# OCMC_RAM1 register map
Vendor: Texas Instruments
Peripheral module from a debugger description file (folder DRA74xP_75xP_76xP_77xP).
Registers are 32-bit, access per field, reset values left out (the file's numbers can be read two ways) unless marked. A register's access mark holds for its fields unless they carry their own. Offsets are as the file gives them; lines under a group give offsets from that group; [hi:lo] are bit positions; {n}, {i} and the like mark numbered series; 'fields as' and 'values as' point back to an identical list; <NAME> marks a mode.

## OCMC_RAM1
0x00 OCMC_ECC_PID ro
  [31:0] REVISION — TI internal data
0x04 OCMC_SYSCONFIG_PM
  [3:2] IDLEMODE rw — Configuration of the local target state management mode. By definition, target can handle read/write transaction as long as it is out of IDLE state.
    0=IP_0 (Force-idle mode: local target's idle state follows (acknowledges) the system's idle requests unconditionally, that is, regardless of the IP module's internal requirements. Backup mode, for debug only.); 1=No-idle mode: local target never enters idle state. Backup mode, for debug only; 2=IP_IP_2 (Smart-idle mode: local target's idle state eventually follows (acknowledges) the system's idle requests, depending on the IP module's internal requirements. IP module shall not generate IRQ-request-related wakeup events.); 3=IP_IP_3 (Smart-idle wakeup-capable mode: local target’s idle state eventually follows (acknowledges) the system’s idle requests, depending on the IP module’s internal requirements. IP module may generate IRQ-request-related wakeup events when in idle state.)
0x08 OCMC_SYSCONFIG_RST
  [0] SW_RST rw — Software reset of the OCM controller configuration and history logic (does not reset L4 interface)
    0=NORMAL_OP (Normal operation (OCM controller is not reset)); 1=RESET (Reset the OCM controller (except its registers). This bit must be set back to 0x0 to resume the normal operation of the OCM Controller.)
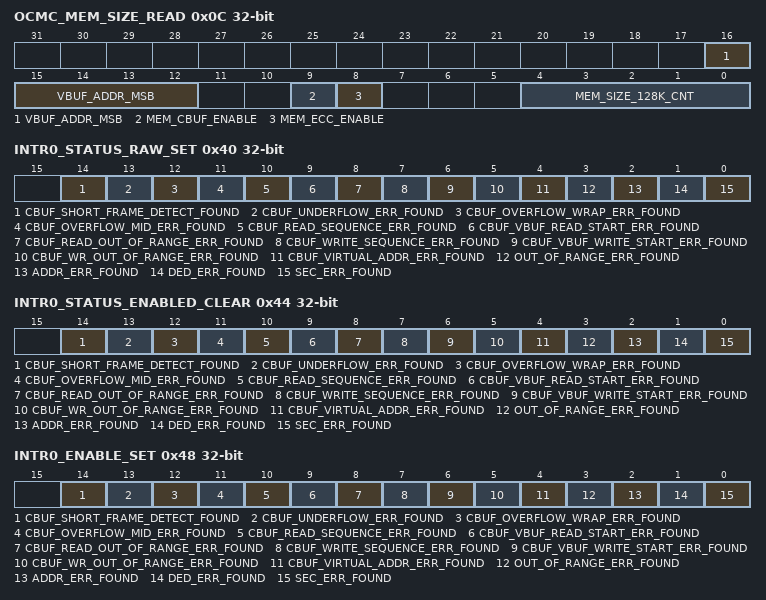
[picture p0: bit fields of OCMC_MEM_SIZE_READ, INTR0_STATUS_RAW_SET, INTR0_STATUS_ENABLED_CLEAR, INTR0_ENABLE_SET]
0x0C OCMC_MEM_SIZE_READ ro — This register provides the status of the OCM Controller configuration.
  [16:12] VBUF_ADDR_MSB — This bit field returns the MSB bit of the valid VBUF address range. The default value of 23 means that the valid VBUF address range is from 0x8000 0000 to 0x80FF FFFF
  [9] MEM_CBUF_ENABLE — Indicates whether CBUF is supported or not.
    0=CBUF_ECC_OFF (CBUF not supported); 1=CBUF_ECC_ON (CBUF supported)
  [8] MEM_ECC_ENABLE — Indicates whether ECC is supported or not.
    0=ECC_OFF (ECC not supported); 1=ECC_ON (ECC supported)
  [4:0] MEM_SIZE_128K_CNT — This bit field indicates how many 128KiB memory blocks are present in the SRAM. Access beyond the memory size reported in the MEM_SIZE_128K_CNT bit field results in an address error interrupt. 0x1: One 128KiB memory block 0x2: Two 128KiB memory blocks ... 0x14: 20 memory blocks of 128KiB
0x40 INTR0_STATUS_RAW_SET — This register contains the raw interrupt status. Read indicates RAW interrupt status (0=inactive, 1=active). Writing 1 will SET the corresponding raw status bit (soft interrupt set). Writing 0 has no effect.
  [14] CBUF_SHORT_FRAME_DETECT_FOUND rw — CBUF detected short frame.
  [13] CBUF_UNDERFLOW_ERR_FOUND rw
  [12] CBUF_OVERFLOW_WRAP_ERR_FOUND rw
  [11] CBUF_OVERFLOW_MID_ERR_FOUND rw
  [10] CBUF_READ_SEQUENCE_ERR_FOUND rw
  [9] CBUF_VBUF_READ_START_ERR_FOUND rw
  [8] CBUF_READ_OUT_OF_RANGE_ERR_FOUND rw
  [7] CBUF_WRITE_SEQUENCE_ERR_FOUND rw
  [6] CBUF_VBUF_WRITE_START_ERR_FOUND rw
  [5] CBUF_WR_OUT_OF_RANGE_ERR_FOUND rw
  [4] CBUF_VIRTUAL_ADDR_ERR_FOUND rw
  [3] OUT_OF_RANGE_ERR_FOUND rw
  [2] ADDR_ERR_FOUND rw
  [1] DED_ERR_FOUND rw
  [0] SEC_ERR_FOUND rw
0x44 INTR0_STATUS_ENABLED_CLEAR access not given — Read indicates ENABLED interrupt status (0=inactive, 1=active). Writing 1 will CLEAR the corresponding enabled status bit. Writing 0 has no effect.
  [14] CBUF_SHORT_FRAME_DETECT_FOUND — CBUF detected short frame (access RW W1toClr)
  [13] CBUF_UNDERFLOW_ERR_FOUND — (access RW W1toClr)
  [12] CBUF_OVERFLOW_WRAP_ERR_FOUND — (access RW W1toClr)
  [11] CBUF_OVERFLOW_MID_ERR_FOUND — (access RW W1toClr)
  [10] CBUF_READ_SEQUENCE_ERR_FOUND — (access RW W1toClr)
  [9] CBUF_VBUF_READ_START_ERR_FOUND — (access RW W1toClr)
  [8] CBUF_READ_OUT_OF_RANGE_ERR_FOUND — (access RW W1toClr)
  [7] CBUF_WRITE_SEQUENCE_ERR_FOUND — (access RW W1toClr)
  [6] CBUF_VBUF_WRITE_START_ERR_FOUND — (access RW W1toClr)
  [5] CBUF_WR_OUT_OF_RANGE_ERR_FOUND — (access RW W1toClr)
  [4] CBUF_VIRTUAL_ADDR_ERR_FOUND — (access RW W1toClr)
  [3] OUT_OF_RANGE_ERR_FOUND — (access RW W1toClr)
  [2] ADDR_ERR_FOUND — (access RW W1toClr)
  [1] DED_ERR_FOUND — (access RW W1toClr)
  [0] SEC_ERR_FOUND — (access RW W1toClr)
0x48 INTR0_ENABLE_SET — Read indicates interrupt enable (0=disabled, 1=enabled) Writing 1 will set the corresponding interrupt enable bit. Writing 0 has no effect. Interrupt_enable_set
  [14] CBUF_SHORT_FRAME_DETECT_FOUND rw — CBUF detected short frame
  [13] CBUF_UNDERFLOW_ERR_FOUND rw
  [12] CBUF_OVERFLOW_WRAP_ERR_FOUND rw
  [11] CBUF_OVERFLOW_MID_ERR_FOUND rw
  [10] CBUF_READ_SEQUENCE_ERR_FOUND rw
  [9] CBUF_VBUF_READ_START_ERR_FOUND rw
  [8] CBUF_READ_OUT_OF_RANGE_ERR_FOUND rw
  [7] CBUF_WRITE_SEQUENCE_ERR_FOUND rw
  [6] CBUF_VBUF_WRITE_START_ERR_FOUND rw
  [5] CBUF_WR_OUT_OF_RANGE_ERR_FOUND rw
  [4] CBUF_VIRTUAL_ADDR_ERR_FOUND rw
  [3] OUT_OF_RANGE_ERR_FOUND rw
  [2] ADDR_ERR_FOUND rw
  [1] DED_ERR_FOUND rw
  [0] SEC_ERR_FOUND rw
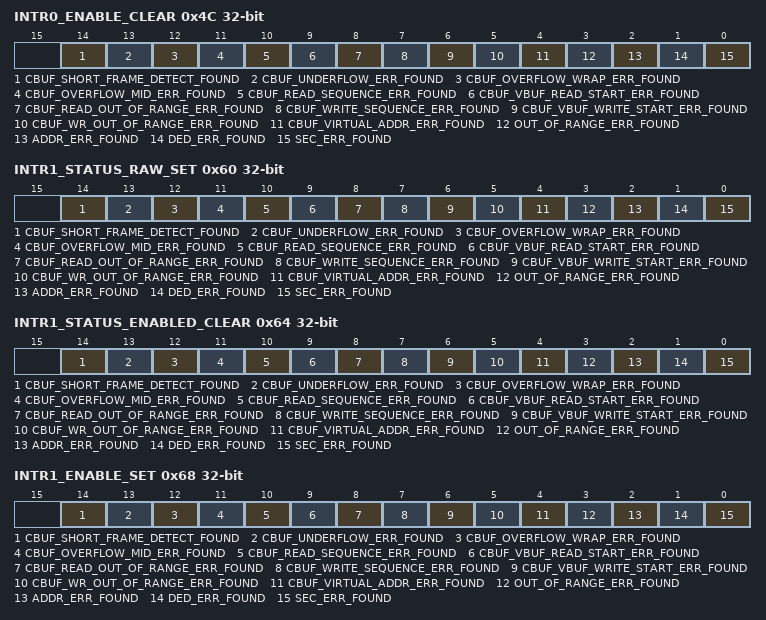
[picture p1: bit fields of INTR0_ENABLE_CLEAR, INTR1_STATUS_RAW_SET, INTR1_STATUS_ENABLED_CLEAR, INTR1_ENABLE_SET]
0x4C INTR0_ENABLE_CLEAR access not given — Read indicates interrupt enable (0=disabled, 1=enabled) Writing 1 will clear interrupt enabled. Writing 0 has no effect. Interrupt_enable_clear
  fields as INTR0_STATUS_ENABLED_CLEAR
0x50 OCMC_INTR0_EOI — This register contains the EOI vector.
  [0] EOI_VECTOR rw
0x60 INTR1_STATUS_RAW_SET — This register contains the raw interrupt status. Read indicates RAW interrupt status (0=inactive, 1=active). Writing 1 will SET the corresponding raw status bit (soft interrupt set). Writing 0 has no effect.
  fields as INTR0_ENABLE_SET
0x64 INTR1_STATUS_ENABLED_CLEAR access not given — Read indicates ENABLED interrupt status (0=inactive, 1=active). Writing 1 will CLEAR the corresponding enabled status bit. Writing 0 has no effect.
  fields as INTR0_STATUS_ENABLED_CLEAR
0x68 INTR1_ENABLE_SET — Read indicates interrupt enable (0=disabled, 1=enabled) Writing 1 will set the corresponding interrupt enable bit. Writing 0 has no effect. Interrupt_enable_set
  fields as INTR0_ENABLE_SET
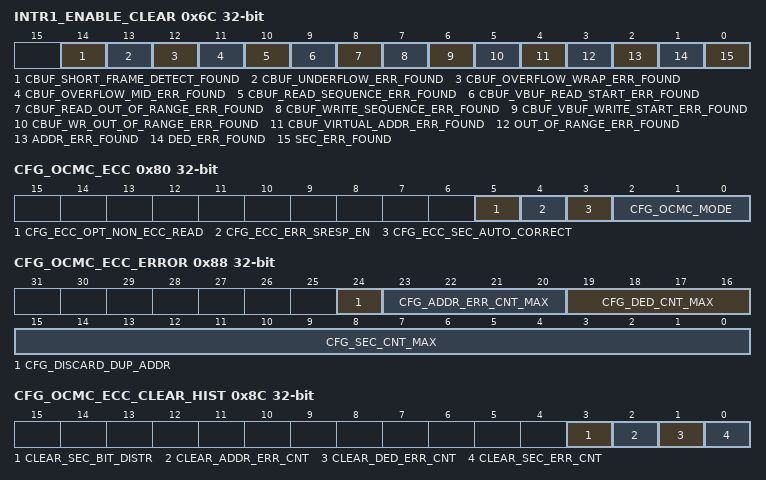
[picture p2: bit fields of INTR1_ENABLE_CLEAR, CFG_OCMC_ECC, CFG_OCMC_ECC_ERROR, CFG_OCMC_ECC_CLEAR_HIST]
0x6C INTR1_ENABLE_CLEAR access not given — Read indicates interrupt enable (0=disabled, 1=enabled) Writing 1 will clear interrupt enabled. Writing 0 has no effect. Interrupt_enable_clear
  fields as INTR0_STATUS_ENABLED_CLEAR
0x70 OCMC_INTR1_EOI — This register contains the EOI vector.
  [0] EOI_VECTOR rw
0x80 CFG_OCMC_ECC
  [5] CFG_ECC_OPT_NON_ECC_READ rw — Optimize read latency for non-ECC read. Returns the data one cycle faster if the read access is from a non-ECC enabled space. 0x0: Disable 0x1: Enable
  [4] CFG_ECC_ERR_SRESP_EN rw — ECC non-correctable error SRESP enable. Enables ERR return on L3 OCP SRESP when a non-correctable data (DED) or address error is detected. 0x0: Disable 0x1: Enable
  [3] CFG_ECC_SEC_AUTO_CORRECT rw — SEC error auto correction mode. Enables the OCM Controller to automatically update the wrong data word with the corrected word. 0x0: Disable 0x1: Enable (If the OCM Controller is performing a read-modify operation for a sub-128b write to an ECC enabled memory, the error found during the read phase will be corrected always regardless of the value of this bit)
  [2:0] CFG_OCMC_MODE rw — OCM Controller memory access modes. 0x0: Non-ECC mode (data access) 0x1: Non-ECC mode (code access) 0x2: Full ECC enabled mode 0x3: Block ECC enabled mode 0x4-0x7: Reserved (internally defaults to 0x0 mode)
0x84 CFG_OCMC_ECC_MEM_BLK
  [19:0] CFG_ECC_ENABLED_128K_BLK rw — ECC memory block enable bits. The active level of each bit is 0x1. Bit [0] -&gt; Address offset range 0x0 to 0x1FFFF Bit [1] -&gt; Address offset range 0x20000 to 0x3FFFF ... Bit [19] -&gt; Address offset range 0x260000 to 0x27FFFF
0x88 CFG_OCMC_ECC_ERROR
  [24] CFG_DISCARD_DUP_ADDR rw — Do not save duplicate error address. This bit applies to the SEC, DED and ADDRERR FIFOs. 0x0: Save the duplicated addresses 0x1: Save only the unique addresses
  [23:20] CFG_ADDR_ERR_CNT_MAX rw — Number of ADDR errors to trigger an interrupt (The value configured must be &gt; 0 to generate an interrupt).
  [19:16] CFG_DED_CNT_MAX rw — Number of DED errors to trigger an interrupt (The value configured must be &gt; 0 to generate an interrupt).
  [15:0] CFG_SEC_CNT_MAX rw — Number of SEC error to trigger an interrupt (The value configured must be &gt; 0 to generate an interrupt).
0x8C CFG_OCMC_ECC_CLEAR_HIST
  [3] CLEAR_SEC_BIT_DISTR rw — Clear stored single error correction (SEC) bit distribution history. Returns 0 on read. 0x0: Reserved (not used) 0x1: Cleares the following registers:
  [2] CLEAR_ADDR_ERR_CNT rw — Clear stored address error history. Returns 0 on read. 0x0: Reserved (not used) 0x1: Clears the
  [1] CLEAR_DED_ERR_CNT rw — Clear stored double error detection (DED) history. Returns 0 on read. 0x0: Reserved (not used) 0x1: Clears the
  [0] CLEAR_SEC_ERR_CNT rw — Clear stored single error correction history. Returns 0 on read. 0x0: Reserved (not used) 0x1: Clears the
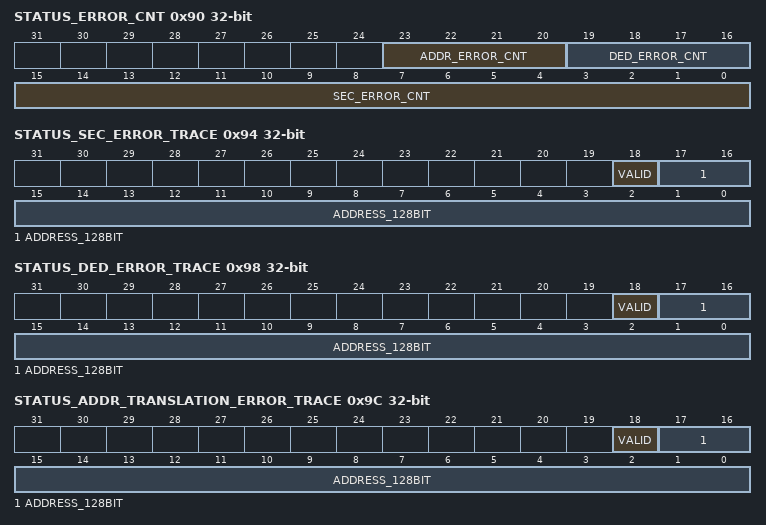
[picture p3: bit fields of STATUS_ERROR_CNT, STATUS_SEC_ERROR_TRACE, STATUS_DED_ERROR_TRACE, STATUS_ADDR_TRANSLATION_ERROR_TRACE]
0x90 STATUS_ERROR_CNT ro — OCM Controller error status
  [23:20] ADDR_ERROR_CNT — Counter for the address errors found. This bit field is reset when 0x1 is written to the
  [19:16] DED_ERROR_CNT — Counter for the double error detections. This bit field is reset when 0x1 is written to the
  [15:0] SEC_ERROR_CNT — Counter for the single errors occured. This bit field is reset when 0x1 is written to the
0x94 STATUS_SEC_ERROR_TRACE ro — SEC error 128-bit memory address
  [18] VALID — SEC FIFO valid addres indication.
    0=ADDRESS_TRACE_FIFO_EMPTY (The SEC FIFO is empty); 1=VALID_ADDRESS_READ (There is a valid address in the SEC FIFO)
  [17:0] ADDRESS_128BIT — SEC error 128-bit memory address (Read from the SEC error address trace fifo)
0x98 STATUS_DED_ERROR_TRACE ro — DED error 128-bit memory address
  [18] VALID — DED FIFO valid addres indication. 0x0: The DED FIFO is empty 0x1: There is a valid address in the DED FIFO
  [17:0] ADDRESS_128BIT — DED error 128-bit memory address (Read from the DED error address trace fifo)
0x9C STATUS_ADDR_TRANSLATION_ERROR_TRACE ro — ADDR error 128-bit memory address
  [18] VALID — ADDRERR FIFO valid addres indication. 0x0: The ADDRERR FIFO is empty 0x1: There is a valid address in the ADDRERR FIFO
  [17:0] ADDRESS_128BIT — ADDR error 128-bit memory address (Read from the ADDR error address trace fifo)
{0xA0+4i} STATUS_SEC_ERROR_DISTR_{i} ro (i=0..3) — SEC data error bit distribution status [{32i+31}:{32i}]
  [31:0] SEC_BIT_ERROR_FOUND — 1 in a bit position means that an SEC error was found at that bit position and corrected
0xB0 STATUS_SEC_ERROR_DISTR_4 ro — SEC ecc code error bit distribution status [7:0]
  [7:0] SEC_ECC_CODE_ERROR_FOUND — ECC Code (excluding the parity bit) error distribution [7:0]. For each bit: 0x0: SEC error not found 0x1: SEC error found In the corresponding bit location
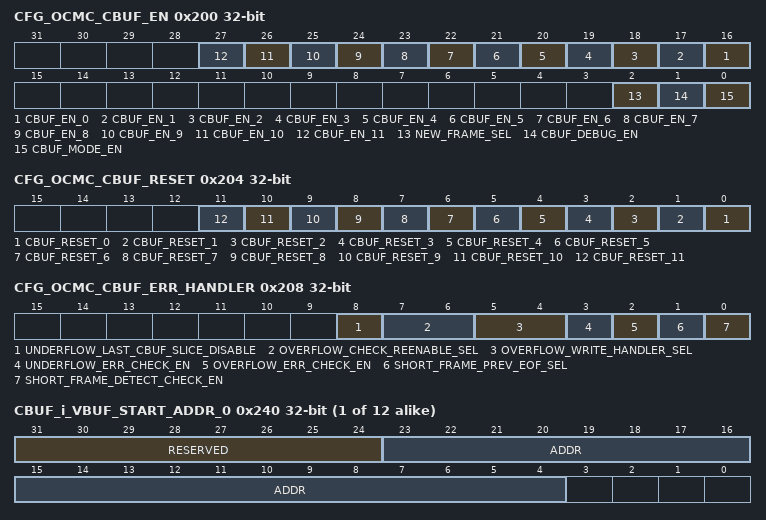
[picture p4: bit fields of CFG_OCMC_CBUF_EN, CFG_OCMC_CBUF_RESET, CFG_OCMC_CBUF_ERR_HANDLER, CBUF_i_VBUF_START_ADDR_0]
0x200 CFG_OCMC_CBUF_EN — CBUF mode enable register
  [n+16] CBUF_EN_{n} rw (n=0..11) — CBUF {n} enable. 0x0: Disable 0x1: Enable
  [2] NEW_FRAME_SEL rw — CBUF New Frame Event Definition Select. 0x0: New frame event flag is set when a VBUF access is made to the base address of the VBUF 0x1: New frame event flag is set when a VBUF access is made to the base CBUF slice address range of the VBUF
  [1] CBUF_DEBUG_EN rw — CBUF Debug Enable Mode. 0x0: Default Normal mode. All CBUF accesses with MReqDebug=1 are rejected. 0x1: Debug mode. MReqDebug Interconnect qualifier is ignored.
  [0] CBUF_MODE_EN rw — CBUF Mode Enable. 0x0: Disable all CBUF address translation 0x1: Enable CBUF address translation
0x204 CFG_OCMC_CBUF_RESET access not given — Writing 1 to bit n will set a reset bit to clear the corresponding CBUF_n address translation logic. Sliding CBUF frame tracking will be cleared so that the CBUF now points to the base of the virtual frame buffer. Normally, a reset is not required since the CBUF logic will clear itself when a VBUF access is to the base of the virtual frame.
  [n] CBUF_RESET_{n} (n=0..11) — cbuf_reset_{n} (access RW W1toClr)
0x208 CFG_OCMC_CBUF_ERR_HANDLER
  [8] UNDERFLOW_LAST_CBUF_SLICE_DISABLE rw — 0x0: Check underflow even when read is from the last CBUF slice 0x1: Disable underflow check when read is from the last CBUF slice
  [7:6] OVERFLOW_CHECK_REENABLE_SEL rw — Overflow check re-enable selection. 0x0: Overflow check is disabled until next wtire to or read from virtual frame start address is detected 0x1: Overflow check is disabled until next write to virtual frame start address is detected 0x2: Overflow check is disabled until next read from virtual frame start address is detected 0x3: Overflow check is re-enabled immediately
  [5:4] OVERFLOW_WRITE_HANDLER_SEL rw — Overflow write handler selection. 0x0: Writes disabled only on CBUF_overflow_wrap cases until next write to virtual frame start address is detected 0x1: Writes disabled on all overflow cases until next write to virtual frame start address is detected 0x2: Writes serviced with CBUF pointer updated even on overflow condition 0x3: Reserved
  [3] UNDERFLOW_ERR_CHECK_EN rw — Underflow chek enable.
    0=UNDERFLOW_CHECK_ENABLE (Underflow check enabled); 1=UNDERFLOW_CHECK_DISABLE (Underflow check disabled)
  [2] OVERFLOW_ERR_CHECK_EN rw — Overflow chek enable.
    0=OVERFLOW_CHECK_ENABLE (Overflow check enabled); 1=OVERFLOW_CHECK_DISABLE (Overflow check disabled)
  [1] SHORT_FRAME_PREV_EOF_SEL rw — 0x0: previous frame EOF history is set if the last write address is equal to the VBUF frame end address 0x1: previous frame EOF history is set if the last write address is in the Last CBUF slice
  [0] SHORT_FRAME_DETECT_CHECK_EN rw — Short frame detection enable.
    0=SHORT_FRAME_DETECT_ENABLE (Detection enabled); 1=SHORT_FRAME_DETECT_DISABLE (Detection disabled)
0x20C STATUS_CBUF_WR_OUT_OF_RANGE_ERR access not given
  [11:0] CBUF_ERR — Indicates that the CBUF write address is out of the CBUF range. Each bit indicates the error of this type for CBUF[n], where n = 0 to 11. Writing 0x1 to bit [n] clears the status of CBUF[n]. Reading 0x1 from bit [n] means that the status is set. (access RW W1toClr)
0x210 STATUS_CBUF_WR_VBUF_START_ERR access not given
  [11:0] CBUF_ERR — CBUF write is not to the base address at vbuf access start. Each bit indicates the error of this type for CBUF[n], where n = 0 to 11. Writing 0x1 to bit [n] clears the status of CBUF[n]. Reading 0x1 from bit [n] means that the status is set. (access RW W1toClr)
0x214 STATUS_CBUF_WR_ADDR_SEQ_ERROR access not given
  [11:0] CBUF_ERR — CBUF address is not incrementing in raster scan order. Each bit indicates the error of this type for CBUF[n], where n = 0 to 11. Writing 0x1 to bit [n] clears the status of CBUF[n]. Reading 0x1 from bit [n] means that the status is set. (access RW W1toClr)
0x218 STATUS_CBUF_RD_OUT_OF_RANGE_ERROR access not given
  [11:0] CBUF_ERR — Indicates that the CBUF read address is out of the CBUF range. Each bit indicates the error of this type for CBUF[n], where n = 0 to 11. Writing 0x1 to bit [n] clears the status of CBUF[n]. Reading 0x1 from bit [n] means that the status is set. (access RW W1toClr)
0x21C STATUS_CBUF_VBUF_RD_START_ERROR access not given
  [11:0] CBUF_ERR — CBUF read is not from the base address at VBUF access start. Each bit indicates the error of this type for CBUF[n], where n = 0 to 11. Writing 0x1 to bit [n] clears the status of CBUF[n]. Reading 0x1 from bit [n] means that the status is set. (access RW W1toClr)
0x220 STATUS_CBUF_RD_ADDR_SEQ_ERROR access not given
  [11:0] CBUF_ERR — CBUF read address is not incrementing in raster scan order. Each bit indicates the error of this type for CBUF[n], where n = 0 to 11. Writing 0x1 to bit [n] clears the status of CBUF[n]. Reading 0x1 from bit [n] means that the status is set. (access RW W1toClr)
0x224 STATUS_CBUF_OVERFLOW_MID access not given
  [11:0] CBUF_ERR — CBUF overflow condition detected in the middle of a frame. Each bit indicates the error of this type for CBUF[n], where n = 0 to 11. Writing 0x1 to bit [n] clears the status of CBUF[n]. Reading 0x1 from bit [n] means that the status is set. (access RW W1toClr)
0x228 STATUS_CBUF_OVERFLOW_WRAP access not given
  [11:0] CBUF_ERR — CBUF overflow condition detected during buffer switching. Each bit indicates the error of this type for CBUF[n], where n = 0 to 11. Writing 0x1 to bit [n] clears the status of CBUF[n]. Reading 0x1 from bit [n] means that the status is set. (access RW W1toClr)
0x22C STATUS_CBUF_UNDERFLOW access not given
  [11:0] CBUF_ERR — CBUF underflow condition detected. Each bit indicates the error of this type for CBUF[n], where n = 0 to 11. Writing 0x1 to bit [n] clears the status of CBUF[n]. Reading 0x1 from bit [n] means that the status is set. (access RW W1toClr)
0x230 STATUS_CBUF_SHORT_FRAME_DETECT access not given
  [11:0] CBUF_ERR — CBUF short frame detected. Each bit indicates the error of this type for CBUF[n], where n = 0 to 11. Writing 0x1 to bit [n] clears the status of CBUF[n]. Reading 0x1 from bit [n] means that the status is set. (access RW W1toClr)
{0x240+0x16*i} CBUF_i_VBUF_START_ADDR_{i} (i=0..11)
  [31:24] RESERVED ro — The virtual address range is determined by theOCMC_MEM_SIZE_READ[16:12] VBUF_ADDR_MSB bit field. For default value of 23, the valid VBUF address is 0x80xx_xxxx. Writing to this field above the MSB bit returned by VBUF_ADDR_MSB will be ignored and reading will return all zeroes except for bit[31] = 1.
  [23:4] ADDR rw — Virtual frame start address for this CBUF - bits [23:4]
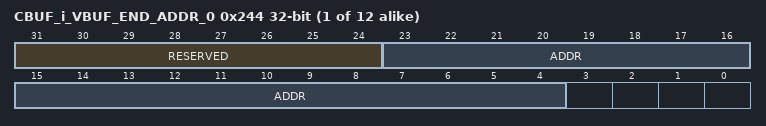
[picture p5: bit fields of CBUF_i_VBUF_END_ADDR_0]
{0x244+0x16*i} CBUF_i_VBUF_END_ADDR_{i} (i=0..11)
  [31:24] RESERVED ro — The virtual address range is determined by theOCMC_MEM_SIZE_READ[16:12] VBUF_ADDR_MSB bit field. For default value of 23, the valid VBUF address is 0x80xx_xxxx. Writing to this field above the MSB bit returned by VBUF_ADDR_MSB will be ignored and reading will return all zeroes except for bit[31] = 1.
  [23:4] ADDR rw — Virtual frame end address for this CBUF - bits [23:4]
{0x248+0x16*i} CBUF_i_OCMC_START_ADDR_{i} (i=0..11)
  [21:4] ADDR rw — SRAM start address for this CBUF - bits [21:4]
{0x24C+0x16*i} CBUF_i_OCMC_BUF_SIZE_{i} (i=0..11)
  [19:4] BUF_SIZE rw — SRAM size allocated for this CBUF - bits [19:4]
{0x300+8i} CBUF_k_LAST_WR_ADDR_{i} ro (i=0..11)
  [31:0] ADDR — Last virtual write address accessing CBUF
{0x304+8i} CBUF_k_LAST_RD_ADDR_{i} ro (i=0..11)
  [31:0] ADDR — Last virtual read address accessing CBUF
0x360 LAST_ILLEGAL_OCMC_ADDR ro
  [31:0] ADDR — Last Illegal OCMC Address. This register returns the OCMC L3_MAIN address of the last access that was invalidated due to an OUT_OF_RANGE_ERR_FOUND (non-VBUF address) error or any one of the CBUF related access errors (including any write access disabled during overflow error handling).
